# AT91SAM9G10 register map
Vendor: Atmel; File version: 20130207
CPU: 
Registers are 32-bit, read-write, no defined reset value unless marked. A register's access mark holds for its fields unless they carry their own. Offsets are from the block's base; [hi:lo] are bit positions; {n}, {i} and the like mark numbered series; 'fields as' and 'values as' point back to an identical list.

## PIOA — Parallel Input/Output Controller A
Base 0xFFFFF400; register names take the prefix PIOA_
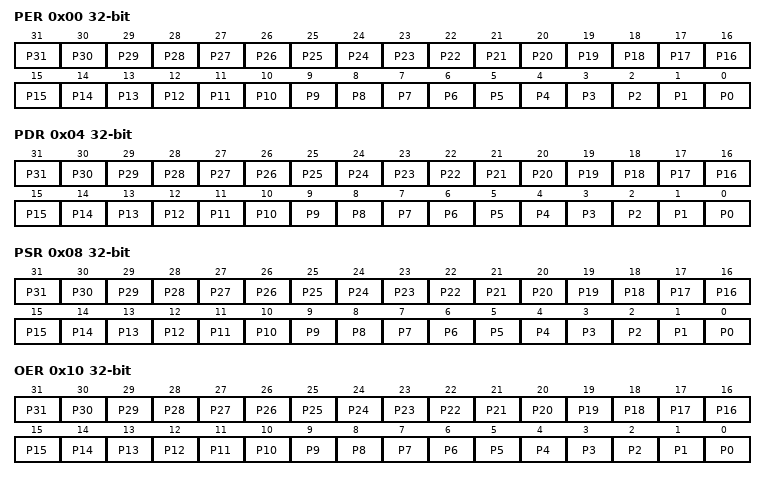
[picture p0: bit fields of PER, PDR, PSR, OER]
0x00 PER wo — PIO Enable Register
  [n] P{n} (n=0..31) — PIO Enable
0x04 PDR wo — PIO Disable Register
  [n] P{n} (n=0..31) — PIO Disable
0x08 PSR ro — PIO Status Register
  [n] P{n} (n=0..31) — PIO Status
0x10 OER wo — Output Enable Register
  [n] P{n} (n=0..31) — Output Enable
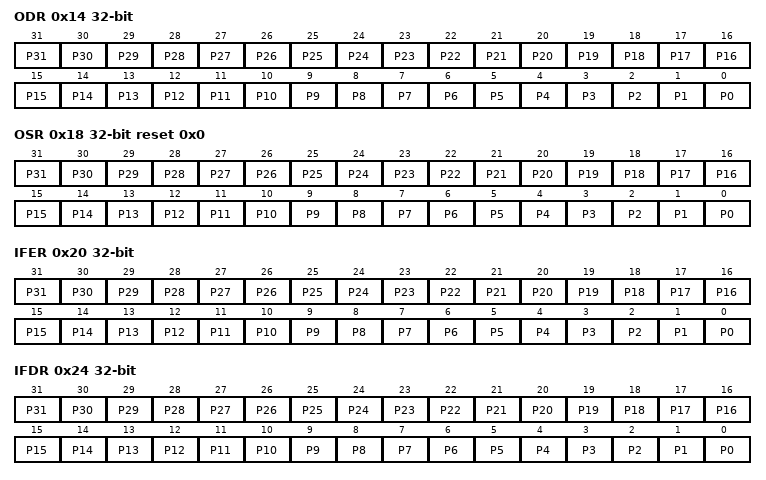
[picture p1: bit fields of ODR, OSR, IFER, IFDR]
0x14 ODR wo — Output Disable Register
  [n] P{n} (n=0..31) — Output Disable
0x18 OSR ro reset 0x0 — Output Status Register
  [n] P{n} (n=0..31) — Output Status
0x20 IFER wo — Glitch Input Filter Enable Register
  [n] P{n} (n=0..31) — Input Filter Enable
0x24 IFDR wo — Glitch Input Filter Disable Register
  [n] P{n} (n=0..31) — Input Filter Disable
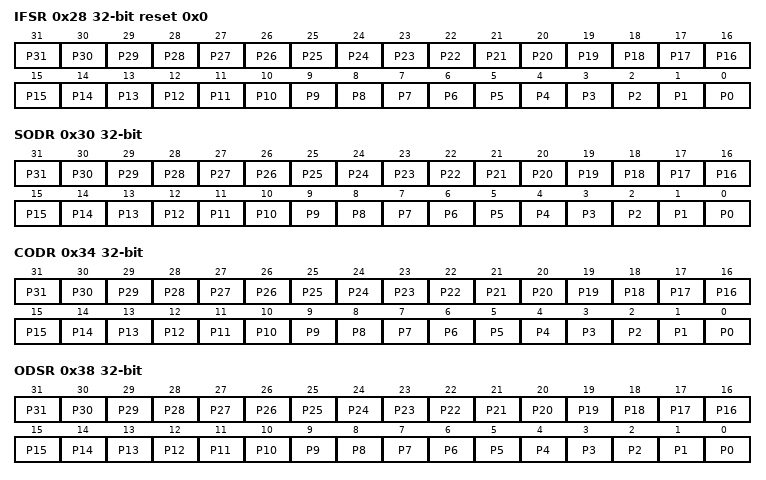
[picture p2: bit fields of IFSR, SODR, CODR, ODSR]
0x28 IFSR ro reset 0x0 — Glitch Input Filter Status Register
  [n] P{n} (n=0..31) — Input Filer Status
0x30 SODR wo — Set Output Data Register
  [n] P{n} (n=0..31) — Set Output Data
0x34 CODR wo — Clear Output Data Register
  [n] P{n} (n=0..31) — Set Output Data
0x38 ODSR — Output Data Status Register
  [n] P{n} (n=0..31) — Output Data Status
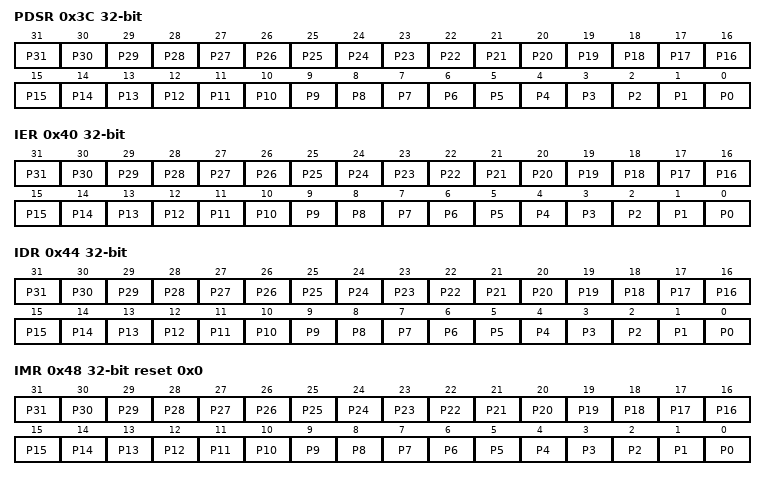
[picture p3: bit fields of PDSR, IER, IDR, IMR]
0x3C PDSR ro — Pin Data Status Register
  [n] P{n} (n=0..31) — Output Data Status
0x40 IER wo — Interrupt Enable Register
  [n] P{n} (n=0..31) — Input Change Interrupt Enable
0x44 IDR wo — Interrupt Disable Register
  [n] P{n} (n=0..31) — Input Change Interrupt Disable
0x48 IMR ro reset 0x0 — Interrupt Mask Register
  [n] P{n} (n=0..31) — Input Change Interrupt Mask
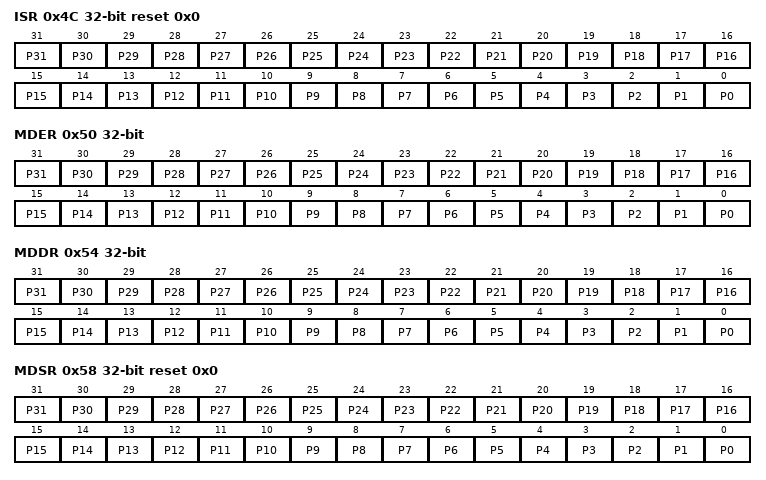
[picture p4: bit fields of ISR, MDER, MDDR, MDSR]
0x4C ISR ro reset 0x0 — Interrupt Status Register
  [n] P{n} (n=0..31) — Input Change Interrupt Status
0x50 MDER wo — Multi-driver Enable Register
  [n] P{n} (n=0..31) — Multi Drive Enable.
0x54 MDDR wo — Multi-driver Disable Register
  [n] P{n} (n=0..31) — Multi Drive Disable.
0x58 MDSR ro reset 0x0 — Multi-driver Status Register
  [n] P{n} (n=0..31) — Multi Drive Status.
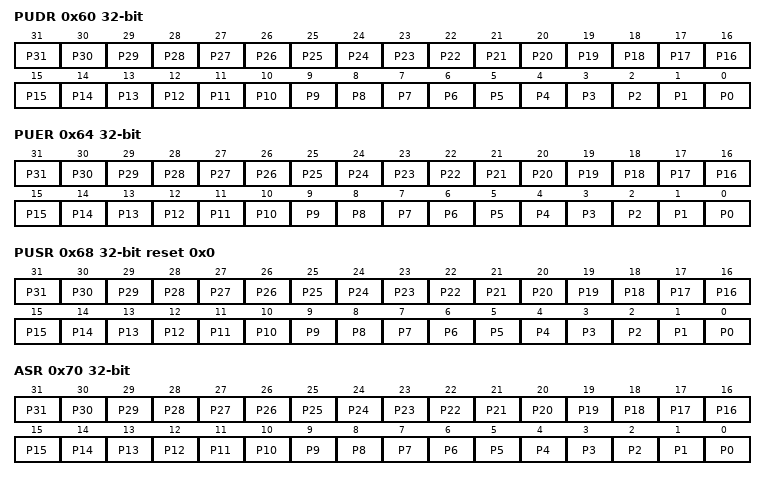
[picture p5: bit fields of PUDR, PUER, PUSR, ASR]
0x60 PUDR wo — Pull-up Disable Register
  [n] P{n} (n=0..31) — Pull Up Disable.
0x64 PUER wo — Pull-up Enable Register
  [n] P{n} (n=0..31) — Pull Up Enable.
0x68 PUSR ro reset 0x0 — Pad Pull-up Status Register
  [n] P{n} (n=0..31) — Pull Up Status.
0x70 ASR wo — Peripheral A Select Register
  [n] P{n} (n=0..31) — Peripheral A Select.
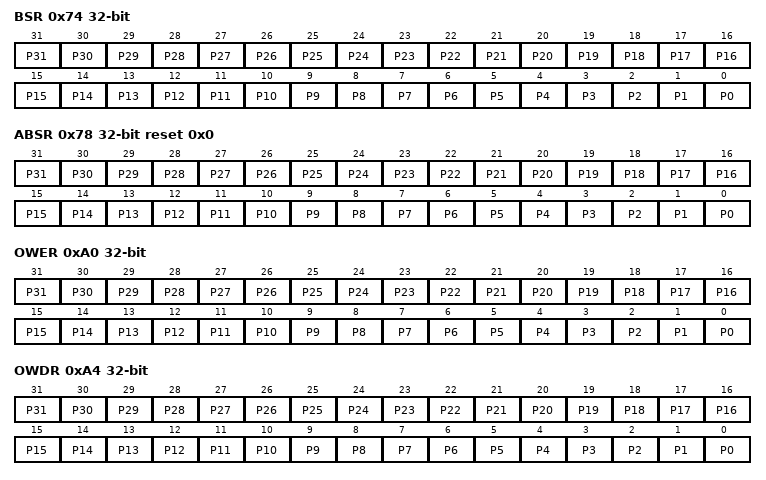
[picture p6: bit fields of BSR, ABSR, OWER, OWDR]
0x74 BSR wo — Peripheral B Select Register
  [n] P{n} (n=0..31) — Peripheral B Select.
0x78 ABSR ro reset 0x0 — AB Status Register
  [n] P{n} (n=0..31) — Peripheral A B Status.
0xA0 OWER wo — Output Write Enable
  [n] P{n} (n=0..31) — Output Write Enable.
0xA4 OWDR wo — Output Write Disable
  [n] P{n} (n=0..31) — Output Write Disable.
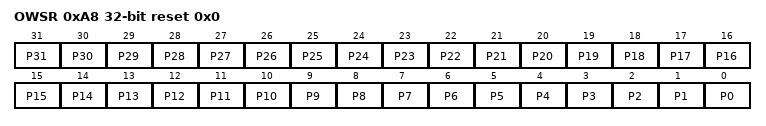
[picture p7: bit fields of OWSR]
0xA8 OWSR ro reset 0x0 — Output Write Status Register
  [n] P{n} (n=0..31) — Output Write Status.

## PIOB — Parallel Input/Output Controller B
Base 0xFFFFF600; register names take the prefix PIOB_
Registers as PIOA.

## PIOC — Parallel Input/Output Controller C
Base 0xFFFFF800; register names take the prefix PIOC_
Registers as PIOA.

## PMC — Power Management Controller
Base 0xFFFFFC00
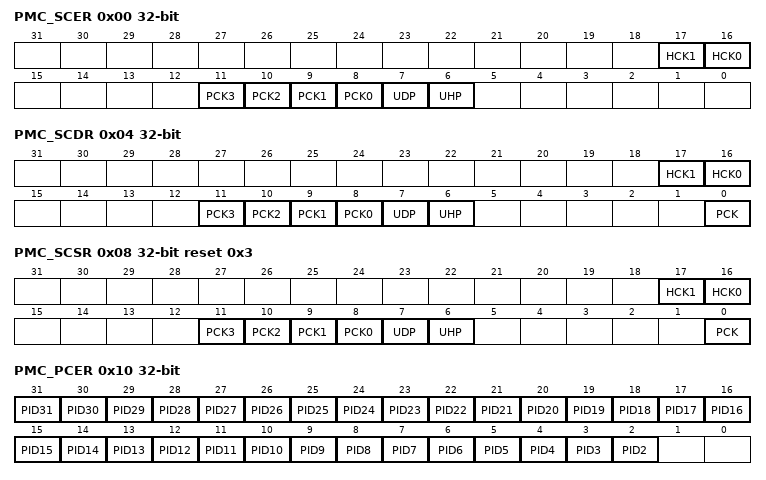
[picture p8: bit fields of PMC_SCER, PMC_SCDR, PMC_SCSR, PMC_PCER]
0x00 PMC_SCER wo — System Clock Enable Register
  [17] HCK1 — HClock 1 Output Enable
  [16] HCK0 — HClock 0 Output Enable
  [n+8] PCK{n} (n=0..3) — Programmable Clock {n} Output Enable
  [7] UDP — USB Device Port Clock Enable
  [6] UHP
0x04 PMC_SCDR wo — System Clock Disable Register
  [17] HCK1 — Hclock 1 Output Disable
  [16] HCK0 — Hclock 0 Output Disable
  [n+8] PCK{n} (n=0..3) — Programmable Clock {n} Output Disable
  [7] UDP — USB Device Port Clock Disable
  [6] UHP
  [0] PCK — Processor Clock Disable
0x08 PMC_SCSR ro reset 0x3 — System Clock Status Register
  [17] HCK1 — HClock Output 1 Status
  [16] HCK0 — HClock Output 0 Status
  [n+8] PCK{n} (n=0..3) — Programmable Clock {n} Output Status
  [7] UDP — USB Device Port Clock Status
  [6] UHP
  [0] PCK — Processor Clock Status
0x10 PMC_PCER wo — Peripheral Clock Enable Register
  [n] PID{n} (n=2..31) — Peripheral Clock {n} Enable
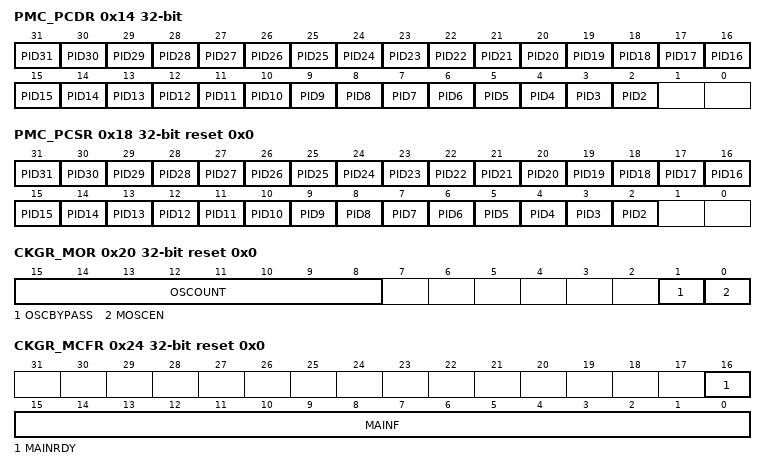
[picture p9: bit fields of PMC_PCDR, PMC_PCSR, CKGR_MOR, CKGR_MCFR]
0x14 PMC_PCDR wo — Peripheral Clock Disable Register
  [n] PID{n} (n=2..31) — Peripheral Clock {n} Disable
0x18 PMC_PCSR ro reset 0x0 — Peripheral Clock Status Register
  [n] PID{n} (n=2..31) — Peripheral Clock {n} Status
0x20 CKGR_MOR reset 0x0 — Main Oscillator Register
  [15:8] OSCOUNT — Main Oscillator Start-up Time
  [1] OSCBYPASS — Oscillator Bypass
  [0] MOSCEN — Main Oscillator Enable
0x24 CKGR_MCFR ro reset 0x0 — Main Clock Frequency Register
  [16] MAINRDY — Main Clock Ready
  [15:0] MAINF — Main Clock Frequency
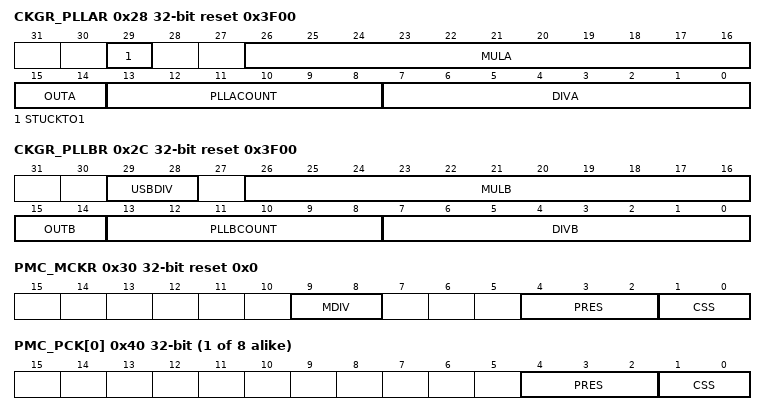
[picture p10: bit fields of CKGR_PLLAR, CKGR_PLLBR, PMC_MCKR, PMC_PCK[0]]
0x28 CKGR_PLLAR reset 0x3F00 — PLL A Register
  [29] STUCKTO1
  [26:16] MULA — PLL A Multiplier
  [15:14] OUTA — PLL A Clock Frequency Range
  [13:8] PLLACOUNT — PLL A Counter
  [7:0] DIVA — Divider A
0x2C CKGR_PLLBR reset 0x3F00 — PLL B Register
  [29:28] USBDIV — Divider for USB Clock
  [26:16] MULB — PLL Multiplier
  [15:14] OUTB — PLLB Clock Frequency Range
  [13:8] PLLBCOUNT — PLL B Counter
  [7:0] DIVB — Divider B
0x30 PMC_MCKR reset 0x0 — Master Clock Register
  [9:8] MDIV — Master Clock Division
  [4:2] PRES — Processor Clock Prescaler
  [1:0] CSS — Master Clock Selection
{0x40+4i} PMC_PCK[{i}] (i=0..7) — Programmable Clock 0 Register
  [4:2] PRES — Programmable Clock Prescaler
  [1:0] CSS — Master Clock Selection
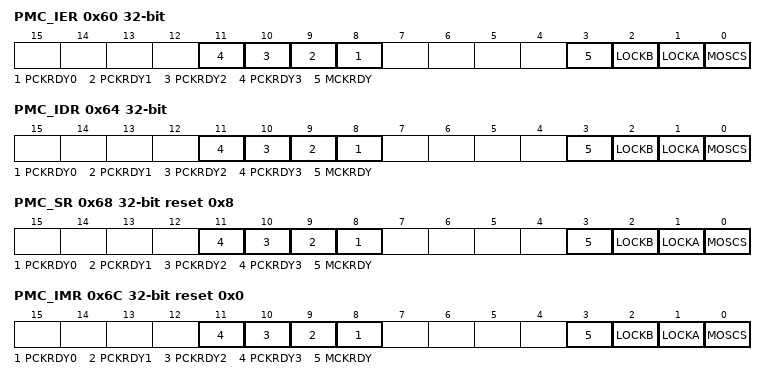
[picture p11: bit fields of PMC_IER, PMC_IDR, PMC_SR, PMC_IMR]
0x60 PMC_IER wo — Interrupt Enable Register
  [n+8] PCKRDY{n} (n=0..3) — Programmable Clock Ready {n} Interrupt Enable
  [3] MCKRDY — Master Clock Ready Interrupt Enable
  [2] LOCKB — PLL B Lock Interrupt Enable
  [1] LOCKA — PLL A Lock Interrupt Enable
  [0] MOSCS — Main Oscillator Status Interrupt Enable
0x64 PMC_IDR wo — Interrupt Disable Register
  [n+8] PCKRDY{n} (n=0..3) — Programmable Clock Ready {n} Interrupt Disable
  [3] MCKRDY — Master Clock Ready Interrupt Disable
  [2] LOCKB — PLL B Lock Interrupt Disable
  [1] LOCKA — PLL A Lock Interrupt Disable
  [0] MOSCS — Main Oscillator Status Interrupt Disable
0x68 PMC_SR ro reset 0x8 — Status Register
  [n+8] PCKRDY{n} (n=0..3) — Programmable Clock Ready Status
  [3] MCKRDY — Master Clock Status
  [2] LOCKB — PLL B Lock Status
  [1] LOCKA — PLL A Lock Status
  [0] MOSCS — MOSCS Flag Status
0x6C PMC_IMR ro reset 0x0 — Interrupt Mask Register
  [n+8] PCKRDY{n} (n=0..3) — Programmable Clock Ready {n} Interrupt Mask
  [3] MCKRDY — Master Clock Ready Interrupt Mask
  [2] LOCKB — PLL B Lock Interrupt Mask
  [1] LOCKA — PLL A Lock Interrupt Mask
  [0] MOSCS — Main Oscillator Status Interrupt Mask
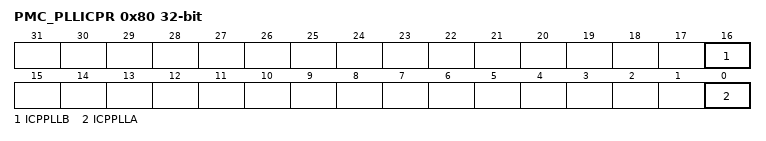
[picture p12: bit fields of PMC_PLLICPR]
0x80 PMC_PLLICPR wo — Charge Pump Current Register
  [16] ICPPLLB — Charge pump current
  [0] ICPPLLA — Charge pump current

## RSTC — Reset Controller
Base 0xFFFFFD00; register names take the prefix RSTC_
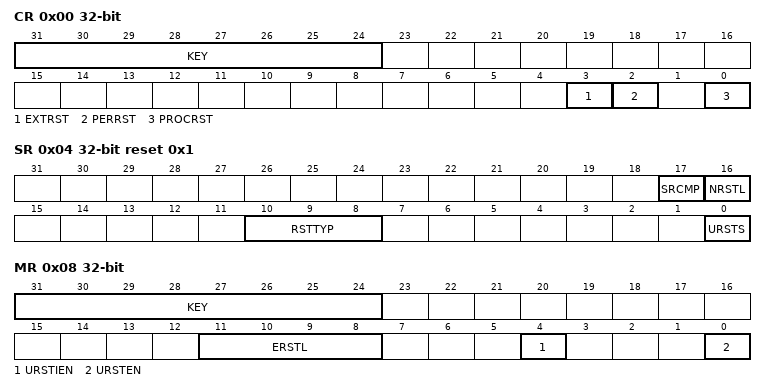
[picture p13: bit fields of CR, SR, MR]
0x00 CR wo — Control Register
  [31:24] KEY — Password
  [3] EXTRST — External Reset
  [2] PERRST — Peripheral Reset
  [0] PROCRST — Processor Reset
0x04 SR ro reset 0x1 — Status Register
  [17] SRCMP — Software Reset Command in Progress
  [16] NRSTL — NRST Pin Level
  [10:8] RSTTYP — Reset Type
  [0] URSTS — User Reset Status
0x08 MR — Mode Register
  [31:24] KEY — Password
  [11:8] ERSTL — External Reset Length
  [4] URSTIEN — User Reset Interrupt Enable
  [0] URSTEN — User Reset Enable

## SHDWC — Shutdown Controller
Base 0xFFFFFD10; register names take the prefix SHDWC_
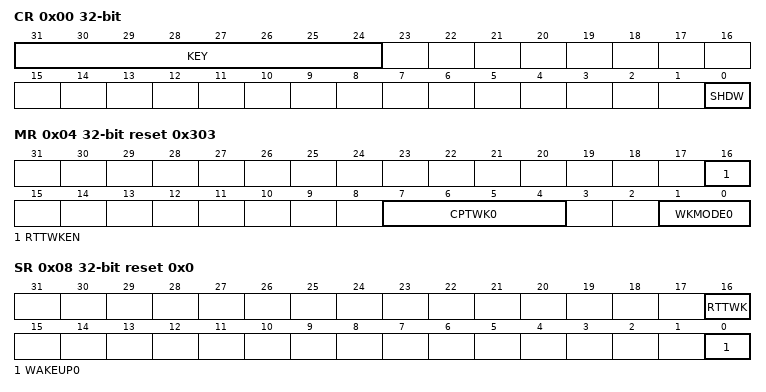
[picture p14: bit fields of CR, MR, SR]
0x00 CR wo — Shutdown Control Register
  [31:24] KEY — Password
  [0] SHDW — Shutdown Command
0x04 MR reset 0x303 — Shutdown Mode Register
  [16] RTTWKEN — Real-time Timer Wake-up Enable
  [7:4] CPTWK0 — Counter on Wake-up 0
  [1:0] WKMODE0 — Wake-up Mode 0
0x08 SR ro reset 0x0 — Shutdown Status Register
  [16] RTTWK — Real-time Timer Wake-up
  [0] WAKEUP0 — Wake-up 0 Status

## RTT — Real-time Timer
Base 0xFFFFFD20; register names take the prefix RTT_
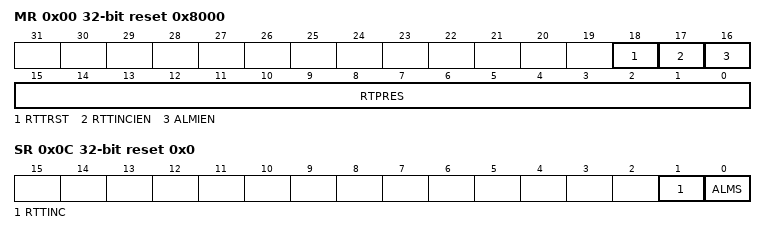
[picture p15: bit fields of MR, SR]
0x00 MR reset 0x8000 — Mode Register
  [18] RTTRST — Real-time Timer Restart
  [17] RTTINCIEN — Real-time Timer Increment Interrupt Enable
  [16] ALMIEN — Alarm Interrupt Enable
  [15:0] RTPRES — Real-time Timer Prescaler Value
0x04 AR reset 0xFFFFFFFF — Alarm Register
  [31:0] ALMV — Alarm Value
0x08 VR ro reset 0x0 — Value Register
  [31:0] CRTV — Current Real-time Value
0x0C SR ro reset 0x0 — Status Register
  [1] RTTINC — Real-time Timer Increment
  [0] ALMS — Real-time Alarm Status

## PIT — Periodic Interval Timer
Base 0xFFFFFD30; register names take the prefix PIT_
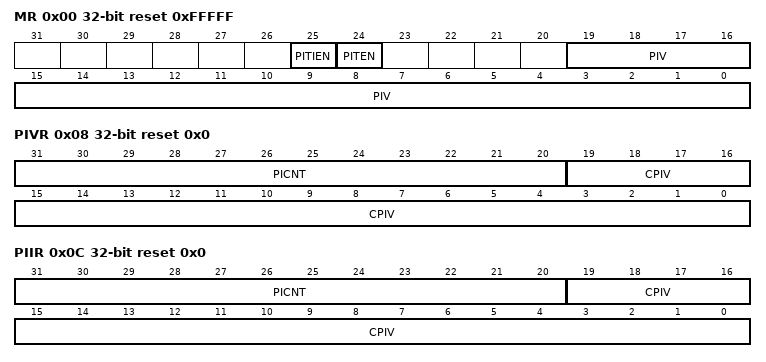
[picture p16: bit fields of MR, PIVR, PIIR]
0x00 MR reset 0xFFFFF — Mode Register
  [25] PITIEN — Periodic Interval Timer Interrupt Enable
  [24] PITEN — Period Interval Timer Enabled
  [19:0] PIV — Periodic Interval Value
0x04 SR ro reset 0x0 — Status Register
  [0] PITS — Periodic Interval Timer Status
0x08 PIVR ro reset 0x0 — Periodic Interval Value Register
  [31:20] PICNT — Periodic Interval Counter
  [19:0] CPIV — Current Periodic Interval Value
0x0C PIIR ro reset 0x0 — Periodic Interval Image Register
  fields as PIVR

## WDT — Watchdog Timer
Base 0xFFFFFD40; register names take the prefix WDT_
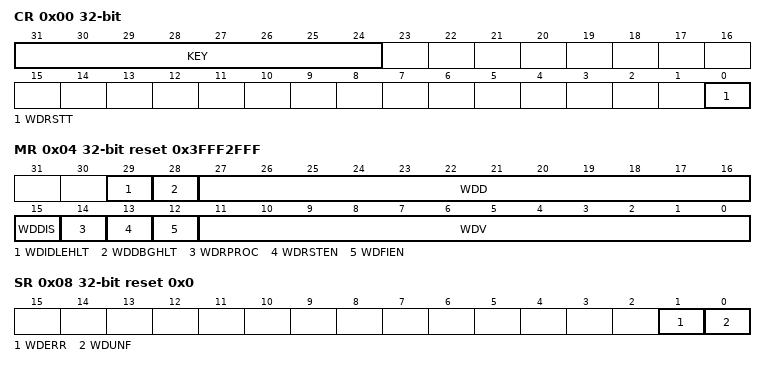
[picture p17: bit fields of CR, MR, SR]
0x00 CR wo — Control Register
  [31:24] KEY — Password
  [0] WDRSTT — Watchdog Restart
0x04 MR reset 0x3FFF2FFF — Mode Register
  [29] WDIDLEHLT — Watchdog Idle Halt
  [28] WDDBGHLT — Watchdog Debug Halt
  [27:16] WDD — Watchdog Delta Value
  [15] WDDIS — Watchdog Disable
  [14] WDRPROC — Watchdog Reset Processor
  [13] WDRSTEN — Watchdog Reset Enable
  [12] WDFIEN — Watchdog Fault Interrupt Enable
  [11:0] WDV — Watchdog Counter Value
0x08 SR ro reset 0x0 — Status Register
  [1] WDERR — Watchdog Error
  [0] WDUNF — Watchdog Underflow

## GPBR — General Purpose Backup Register
Base 0xFFFFFD50; register names take the prefix GPBR_
{0x0+4i} GPBR{i} (i=0..3) — General Purpose Backup Register {i}
  [31:0] GPBR_VALUE{i} — Value of GPBR x
